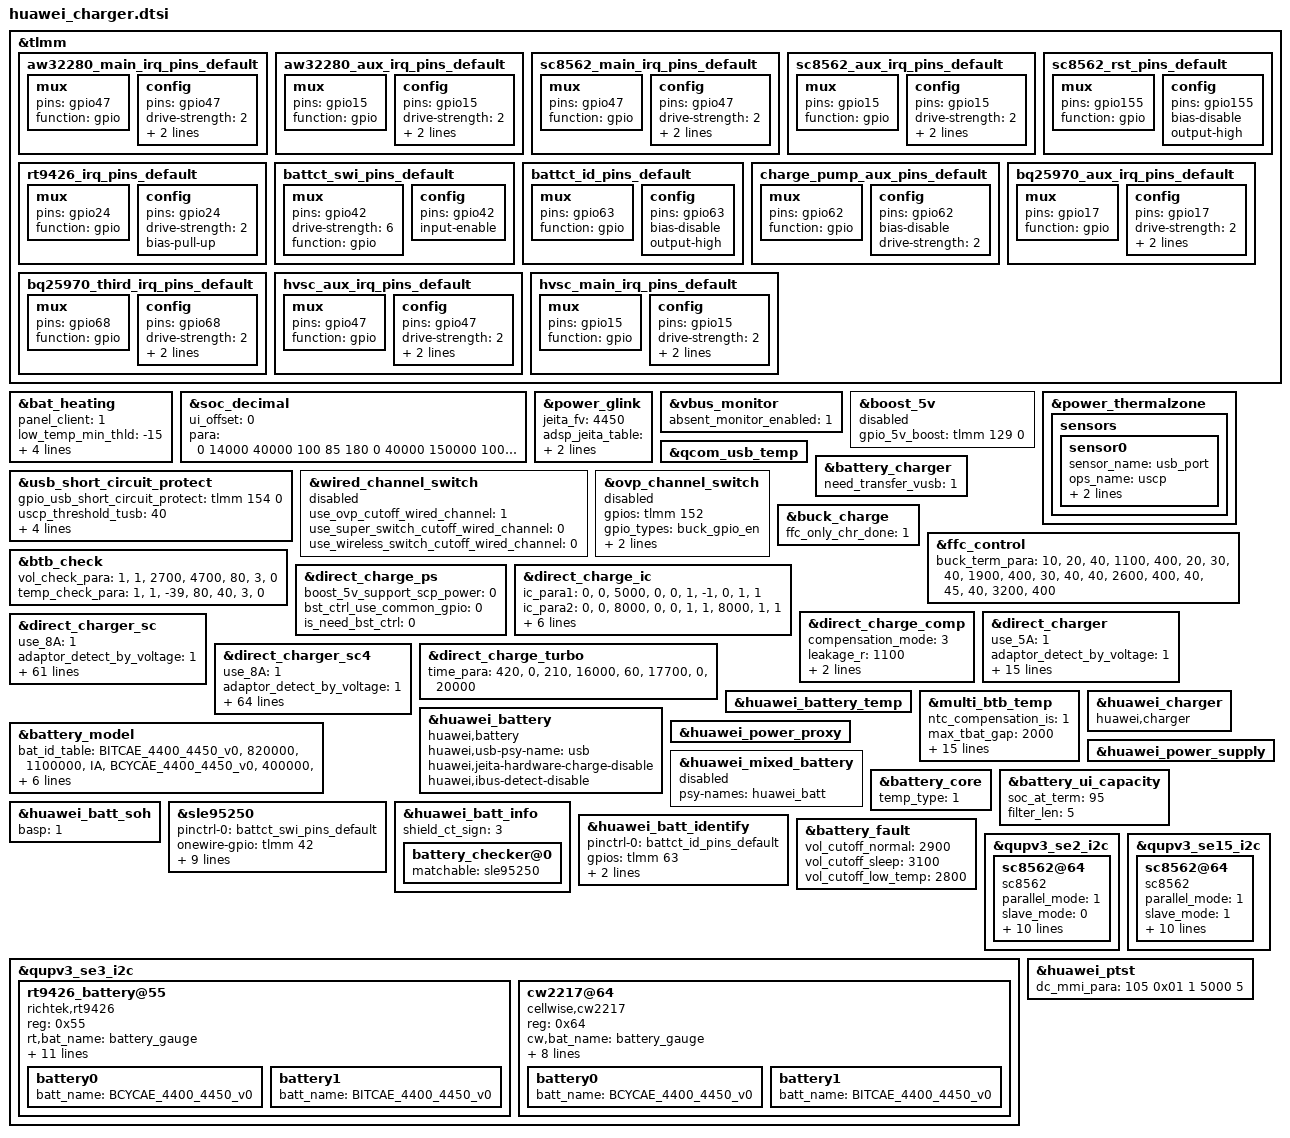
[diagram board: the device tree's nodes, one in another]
&tlmm {
	aw32280_main_irq_pins_default: aw32280_main_irq_pins_default {
		mux {
			pins = "gpio47";
			function = "gpio";
		};
		config {
			pins = "gpio47";
			drive-strength = <2>;
			bias-pull-up;
			input-enable;
		};
	};

	aw32280_aux_irq_pins_default: aw32280_aux_irq_pins_default {
		mux {
			pins = "gpio15";
			function = "gpio";
		};
		config {
			pins = "gpio15";
			drive-strength = <2>;
			bias-pull-up;
			input-enable;
		};
	};

	sc8562_main_irq_pins_default: sc8562_main_irq_pins_default {
		mux {
			pins = "gpio47";
			function = "gpio";
		};
		config {
			pins = "gpio47";
			drive-strength = <2>;
			bias-pull-up;
			input-enable;
		};
	};

	sc8562_aux_irq_pins_default: sc8562_aux_irq_pins_default {
		mux {
			pins = "gpio15";
			function = "gpio";
		};
		config {
			pins = "gpio15";
			drive-strength = <2>;
			bias-pull-up;
			input-enable;
		};
	};

	sc8562_rst_pins_default: sc8562_rst_pins_default {
		mux {
			pins = "gpio155";
			function = "gpio";
		};
		config {
			pins = "gpio155";
			bias-disable;
			output-high;
		};
	};

	rt9426_irq_pins_default: rt9426_irq_pins_default {
		mux {
			pins = "gpio24";
			function = "gpio";
		};
		config {
			pins = "gpio24";
			drive-strength = <2>;
			bias-pull-up;
		};
	};
	battct_swi_pins_default: battct_swi_pins_default {
		mux {
			pins = "gpio42";
			drive-strength = <6>;
			function = "gpio";
		};
		config {
			pins = "gpio42";
			input-enable;
		};
	};
	battct_id_pins_default: battct_id_pins_default {
		mux {
			pins = "gpio63";
			function = "gpio";
		};
		config {
			pins = "gpio63";
			bias-disable;
			output-high;
		};
	};
	charge_pump_aux_pins_default: charge_pump_aux_pins_default {
		/* MCLK4 */
		mux {
			pins = "gpio62";
			function = "gpio";
		};
		config {
			pins = "gpio62";
			bias-disable; /* No PULL */
			drive-strength = <2>; /* 2 MA */
		};
	};

	bq25970_aux_irq_pins_default: bq25970_aux_irq_pins_default {
		mux {
			pins = "gpio17";
			function = "gpio";
		};
		config {
			pins = "gpio17";
			drive-strength = <2>;
			bias-pull-up;
			input-enable;
		};
	};

	bq25970_third_irq_pins_default: bq25970_third_irq_pins_default {
		mux {
			pins = "gpio68";
			function = "gpio";
		};
		config {
			pins = "gpio68";
			drive-strength = <2>;
			bias-pull-up;
			input-enable;
		};
	};

	hvsc_aux_irq_pins_default: hvsc_aux_irq_pins_default {
		mux {
			pins = "gpio47";
			function = "gpio";
		};
		config {
			pins = "gpio47";
			drive-strength = <2>;
			bias-pull-up;
			input-enable;
		};
	};

	hvsc_main_irq_pins_default: hvsc_main_irq_pins_default {
		mux {
			pins = "gpio15";
			function = "gpio";
		};
		config {
			pins = "gpio15";
			drive-strength = <2>;
			bias-pull-up;
			input-enable;
		};
	};
};

&bat_heating {
	panel_client = "1";
	low_temp_min_thld = "-15";
	low_temp_min_ibat = "-550";
	buck_iin_limit = "750";
	temp_para =
		"-32767", "0", "0",
		"0", "5", "-1",
		"5", "10", "400",
		"10", "20", "2500",
		"20", "45", "4500",
		"45", "32767", "0";
	status = "ok";
};

&soc_decimal {
	ui_offset = <0>;
	para = <
		0 14000 40000  100 85  180
		0 40000 150000 100 120 100
		1 20000 27000  100 85  140
		1 27000 100000 100 85  140
	>;
	status = "ok";
};

&power_glink {
	jeita_fv = <4450>;
	adsp_jeita_table = <
		0 5 400 4450
		5 10 2000 4450
		10 45 3000 4450
		45 55 1400 4100
	>;
	battery_adc_channel = <1>;
};

&vbus_monitor {
	status = "ok";
	absent_monitor_enabled = <1>;
};

&boost_5v {
	gpio_5v_boost = <&tlmm 129 0>;    /* GPIO_07 */
	status = "disabled";
};

&power_thermalzone {
	status = "ok";
	sensors{
		sensor0 {
			sensor_name = "usb_port";
			ops_name = "uscp";
			adc_channel = <0>;
			ntc_index = <5>;
		};
	};
};

&qcom_usb_temp {
	status = "ok";
};

&battery_charger {
	need_transfer_vusb = <1>;
};

&usb_short_circuit_protect {
	gpio_usb_short_circuit_protect = <&tlmm 154 0>; /* GPIO_154 */
	uscp_threshold_tusb = <40>;
	open_mosfet_temp = <30>;
	close_mosfet_temp = <10>;
	open_hiz_temp = <30>;
	interval_switch_temp = <15>;
	status = "ok";
};

&wired_channel_switch {
	use_ovp_cutoff_wired_channel = <1>;
	use_super_switch_cutoff_wired_channel = <0>;
	use_wireless_switch_cutoff_wired_channel = <0>;
	status = "disabled";
};

&ovp_channel_switch {
	gpios = <&tlmm 152 0>;
	gpio_types = "buck_gpio_en";
	gpio_en_status = <0>;
	gpio_low_by_set_input = <0>;
	status = "disabled";
};
&buck_charge {
	ffc_only_chr_done = <1>;
	status = "ok";
};

&ffc_control {
	status = "ok";
	buck_term_para =
		"10", "20", "40", "1100", "400",
		"20", "30", "40", "1900", "400",
		"30", "40", "40", "2600", "400",
		"40", "45", "40", "3200", "400";
};

&btb_check {
	vol_check_para = "1", "1", "2700", "4700", "80", "3", "0";
	temp_check_para = "1", "1", "-39", "80", "40", "3", "0";
	status = "ok";
};

&direct_charge_ps {
	boost_5v_support_scp_power = <0>;
	bst_ctrl_use_common_gpio = <0>;
	is_need_bst_ctrl = <0>;
	status = "ok";
};

&direct_charge_ic {
	/* The IC_PARA table is used to find the relationship between chip and path */
	/* the chip's current passing capacity */
	/* and the sampling points of battery voltage and current */
	/* ic_index  path_index  max_ibat  ibat_sample_point  vbat_sample_point */
	ic_para1 =
		"0", "0", "5000", "0", "0",
		"1", "-1", "0", "1", "1";
	ic_para2 =
		"0", "0", "8000", "0", "0",
		"1", "1", "8000", "1", "1";
	ic_para3 =
		"0", "0", "12000", "0", "0",
		"1", "1", "12000", "1", "1";
	mode_para =
		"lvc_mode", "ic_para1",
		"sc_mode", "ic_para2",
		"sc4_mode", "ic_para3";
	use_two_stage = <0>;
	use_coul_ibat = <1>;
	use_coul_vbat = <0>;
	status = "ok";
};

&direct_charge_comp {
	compensation_mode = <3>;
	leakage_r = <1100>;
	compensate_r = <4>;
	/* The vbat_samp_point_para table is used to find the comp relationship between chips */
	/* Calculate all compensation values of the same index */
	/* as the final compensation of the chip */
	/* Separately calculate positive and negative poles */
	/* ic_index  p_index  n_index */
	vbat_samp_point_para =
		"0", "0", "0",
		"1", "1", "0";
	status = "ok";
};

&direct_charger {
	use_5A = <1>;
	adaptor_detect_by_voltage = <1>;
	need_wired_sw_off = <0>;
	volt_para =
		"4300", "5000", "4000",
		"4440", "4000", "1200";
	all_stage_compensate_r_en = <1>;
	cc_cable_detect_enable = <1>;
	vol_err_th = <250>;
	full_path_res_max = <300>;
	scp_work_on_charger = <1>;
	init_delt_vset = <300>;
	standard_cable_full_path_res_max = <300>;
	first_cc_stage_timer_in_min = <5>;
	stage_need_to_jump = "1";
	low_temp_hysteresis = <5>;
	temp_para =
		"-32767", "10", "0",
		"10", "45", "5000",
		"45", "32767", "0";
	rt_test_para =
		"1000", "105"; /* rt_curr_th rt_test_time */
	status = "ok";

};

&direct_charger_sc {
	use_8A = <1>;
	adaptor_detect_by_voltage = <1>;
	adaptor_antifake_check_enable = <1>;
	adaptor_antifake_key_index = <2>;
	dc_volt_ratio = <2>;
	cur_inversion = <3500>;
	max_adaptor_vset = <11000>;
	init_adapter_vset = <8800>;
	vol_err_th = <500>;
	adaptor_leakage_current_th = <600>;
	high_temp_hysteresis = <1>;
	init_delt_vset = <450>;
	vstep = <20>;
	min_dc_bat_vol = <3450>;
	max_dc_bat_vol = <4380>;
	delta_err = <200>;
	stop_charging_sleep_enable = <1>;
	support_multi_ic = <1>;
	multi_ic_ibat_th = <4000>;
	second_resist_check_en = <1>;
	ui_max_pwr = <40000>;
	product_max_pwr = <66000>;
	max_current_for_none_standard_cable = <6000>;
	volt_para =
		"4150", "13500", "8800",
		"4250", "8800", "6600",
		"4300", "6600", "4400",
		"4450", "4400", "3200",
		"4470", "3200", "1200";
	volt_para1 =
		"4100", "20000", "17600",
		"4250", "17600", "13200",
		"4300", "13200", "8800",
		"4400", "8800", "6600",
		"4450", "6600", "5300",
		"4470", "5300", "1900";
	volt_para2 =
		"4100", "20000", "17600",
		"4250", "17600", "13200",
		"4300", "13200", "8800",
		"4400", "8800", "6600",
		"4450", "6600", "5300",
		"4470", "5300", "2600";
	volt_para3 =
		"4100", "20000", "17600",
		"4250", "17600", "13200",
		"4300", "13200", "8800",
		"4400", "8800", "6600",
		"4450", "6600", "5300",
		"4470", "5300", "3200";
	time_para =
		"720", "8500",
		"540", "9000",
		"480", "11000",
		"0", "20000";
	bat_para =
		"CAE", "10", "20", "volt_para",
		"CAE", "20", "30", "volt_para1",
		"CAE", "30", "40", "volt_para2",
		"CAE", "40", "45", "volt_para3",
		"default", "10", "20", "volt_para",
		"default", "20", "30", "volt_para1",
		"default", "30", "40", "volt_para2",
		"default", "40", "45", "volt_para3";
	vstep_para =
			"2000", "80";
	cc_cable_detect_enable = <1>;
	full_path_res_max = <450>;
	scp_work_on_charger = <1>;
	standard_cable_full_path_res_max = <450>;
	first_cc_stage_timer_in_min = <14>;
	stage_need_to_jump = "-1";
	low_temp_hysteresis = <5>;
	rt_test_para =
		/* first:sc second:mainsc third:auxsc */
		"500", "105",
		"500", "105",
		"500", "105";
	current_ratio =
		"3", "7", "14", "2", "-1",
		"3", "8", "12", "1", "8000",
		"0", "8", "12", "0", "0";
	vbat_error =
		"3", "120", "2", "-1",
		"3", "80", "1", "0";
	temp_para =
		"-32767", "10", "0",
		"10", "45", "12500",
		"45", "32767", "0";
	resist_para =
		"0", "260", "6000",
		"260", "450", "4000";
	std_resist_para =
		"0", "300", "12000",
		"300", "450", "8000";
	second_resist_para =
		"0", "220", "12000",
		"220", "450", "8000";
	ctc_second_resist_para =
		"0", "250", "12000",
		"250", "450", "8000";
	status = "ok";
};

&direct_charger_sc4 {
	use_8A = <1>;
	adaptor_detect_by_voltage = <1>;
	adaptor_antifake_check_enable = <1>;
	adaptor_antifake_key_index = <2>;
	dc_volt_ratio = <4>;
	cur_inversion = <7500>;
	init_delt_vset = <900>;
	max_adaptor_vset = <20000>;
	init_adapter_vset = <15000>;
	vol_err_th = <500>;
	adaptor_leakage_current_th = <600>;
	high_temp_hysteresis = <1>;
	vstep = <40>;
	min_dc_bat_vol = <3450>;
	max_dc_bat_vol = <4380>;
	delta_err = <200>;
	multi_ic_ibat_th = <5000>;
	second_resist_check_en = <1>;
	ui_max_pwr = <40000>;
	product_max_pwr = <100000>;
	ctc_cable_full_path_res_max = <600>;
	max_current_for_none_standard_cable = <12000>;
	volt_para =
		"4150", "13500", "8800",
		"4250", "8800", "6600",
		"4300", "6600", "4600",
		"4450", "4600", "3400",
		"4470", "3400", "1100";
	volt_para1 =
		"4100", "20000", "17600",
		"4250", "17600", "13200",
		"4300", "13200", "9000",
		"4400", "9000", "6800",
		"4450", "6800", "5500",
		"4470", "5500", "1900";
	volt_para2 =
		"4100", "20000", "17600",
		"4250", "17600", "13200",
		"4300", "13200", "9000",
		"4400", "9000", "6800",
		"4450", "6800", "5500",
		"4470", "5500", "2600";
	volt_para3 =
		"4100", "20000", "17600",
		"4250", "17600", "13200",
		"4300", "13200", "9000",
		"4400", "9000", "6800",
		"4450", "6800", "5500",
		"4470", "5500", "3200";
	time_para =
		"300", "0",
		"180", "14000",
		"60", "16000",
		"0", "20000";
	bat_para =
		"CAE", "10", "20", "volt_para",
		"CAE", "20", "30", "volt_para1",
		"CAE", "30", "40", "volt_para2",
		"CAE", "40", "45", "volt_para3",
		"default", "10", "20", "volt_para",
		"default", "20", "30", "volt_para1",
		"default", "30", "40", "volt_para2",
		"default", "40", "45", "volt_para3";
	vstep_para =
			"2000", "80";
	all_stage_compensate_r_en = <1>;
	cc_cable_detect_enable = <1>;
	full_path_res_max = <450>;
	scp_work_on_charger = <1>;
	standard_cable_full_path_res_max = <450>;
	first_cc_stage_timer_in_min = <14>;
	stage_need_to_jump = "-1";
	low_temp_hysteresis = <5>;
	support_multi_ic = <1>;
	need_boost_5v = <0>;
	rt_test_para =
		/* first:sc second:mainsc third:auxsc */
		"500", "105",
		"500", "105",
		"500", "105";
	current_ratio =
		"3", "8", "14", "2", "-1",
		"3", "7", "12", "1", "8000",
		"0", "7", "12", "0", "0";
	vbat_error =
		"3", "120", "2", "-1",
		"3", "80", "1", "0";
	temp_para =
		"-32767", "10", "0",
		"10", "45", "20000",
		"45", "32767", "0";
	resist_para =
		"0", "260", "12000",
		"260", "450", "8000";
	std_resist_para =
		"0", "300", "20000",
		"300", "450", "16000";
	second_resist_para =
		"0", "260", "20000",
		"260", "450", "16000";
	ctc_second_resist_para =
		"0", "250", "20000",
		"250", "450", "16000";
	status = "ok";
};

&direct_charge_turbo {
	status = "ok";
        time_para =
                "420", "0",
                "210", "16000",
                "60", "17700",
                "0", "20000";
};

&huawei_battery_temp {
	status = "ok";
};

&multi_btb_temp {
	status = "ok";
	ntc_compensation_is = <1>;
	max_tbat_gap = <2000>;
	comp_para =
		"17000", "28000",
		"15000", "25000",
		"14000", "23000",
		"13000", "20000",
		"11000", "16000",
		"10000", "13000",
		"9000", "12000",
		"7000", "10000",
		"6000", "8000",
		"5000", "6000",
		"4000", "4000",
		"3000", "3000",
		"2000", "2000";
	comp_para1 =
		"0", "0";
	comp_para_fix =
		"17000", "19000",
		"15000", "17000",
		"14000", "15000",
		"13000", "14000",
		"11000", "12000",
		"10000", "11000",
		"9000", "9000",
		"8000", "8000",
		"6000", "7000",
		"5000", "5000",
		"4000", "4000",
		"3000", "3000",
		"2000", "2000";
	need_different_comp = <1>; /* config "1" if different battery type use different comp para */
	/* By default, only 2 columns of sensor-names need to be configured */
	/* just if need_different_comp is "1", 3 columns of sensor-names need to be configured */
	/* sensor name, default compensation para, compensation para for another battery type */
	sensor-names =
		"battery_gauge", "comp_para", "comp_para_fix",
		"bk_battery", "comp_para1", "comp_para1";
};

&huawei_battery {
	compatible = "huawei,battery";
	status = "ok";
	huawei,usb-psy-name = "usb";
	huawei,jeita-hardware-charge-disable;
	huawei,ibus-detect-disable;
};

&huawei_charger {
	compatible = "huawei,charger";
	status = "ok";
};


&battery_model {
	bat_id_table =
		"BITCAE_4400_4450_v0", "820000", "1100000", "IA",
		"BCYCAE_4400_4450_v0", "400000", "630000", "CA";
	design_fcc = <4400>;
	id_adc_channel = <0>; /* useless but necessary for Qcom, set 0 as default */
	bat_identifier_index = <10>; /* the 11th digit of sn is used as identifier */
	bat_identifier_len = <1>; /* the length of identifier */
	bat_types_pattern =
		"cob", "[B]";
	status = "ok";
};

&huawei_power_proxy {
	status = "ok";
};

&huawei_power_supply {
	 status = "ok";
};

&huawei_mixed_battery {
	psy-names = "huawei_batt";
	status = "disabled";
};

&battery_core {
	temp_type = <1>;
	status = "ok";
};

&battery_ui_capacity {
	soc_at_term = <95>;
	filter_len = <5>;
	status = "ok";
};

&huawei_batt_soh {
	basp = <1>;
	status = "ok";
};

&sle95250 {
        pinctrl-names = "default";
        pinctrl-0 = <&battct_swi_pins_default>;
        onewire-gpio = <&tlmm 42 0>;
        product_id0 = <1>;
        product_id2 = <3>;
        gpio_sn_mode_val = <0>;
        dip_check = <0>;
        gpio_swi = <42>;
        gpio_id_mode = <63>;
        gpio_swi_drv = <2>;
        tau = /bits/ 8 <0xa>;
        tau_fastboot = <7>;
        status = "ok";
};

&huawei_batt_info {
        status = "ok";
        shield_ct_sign = <3>;
        battery_checker@0 {
                matchable = <&sle95250>;
                status = "ok";
        };
};

&huawei_batt_identify {
	pinctrl-names = "default";
	pinctrl-0 = <&battct_id_pins_default>;
	gpios = <&tlmm 63 0>;
	id_voltage_gpiov = <0 1>;
	id_sn_gpiov = <0 0>;
	status = "ok";
};

&battery_fault {
	vol_cutoff_normal = <2900>;
	vol_cutoff_sleep = <3100>;
	vol_cutoff_low_temp = <2800>;
	status = "ok";
};

&qupv3_se2_i2c {
	#address-cells = <1>;
	#size-cells = <0>;
	status = "ok";
	sc8562@64{
		compatible = "sc8562";
		parallel_mode = <1>;
		slave_mode = <0>;
		ic_role = <0>;
		reg = <0x64>;
		gpio_reset = <&tlmm 155 0>;
		fcp_support = <1>;
		scp_support = <1>;
		pinctrl-names = "default";
		pinctrl-0 = <&sc8562_main_irq_pins_default>;
		gpio_int = <&tlmm 47 0>;
		gpio_enable = <&tlmm 62 0>;
		sense_r_config = <10>;
		sense_r_actual = <10>;
		status = "ok";
	};
};

&qupv3_se3_i2c {
	#address-cells = <1>;
	#size-cells = <0>;
	status = "ok";
	rt9426_battery@55{
		reg = <0x55>;
		compatible = "richtek,rt9426";
		rt,bat_name = "battery_gauge";
		pinctrl-names = "default";
		pinctrl-0 = <&rt9426_irq_pins_default>;
		rt9426,gpio-intb = <&tlmm 24 0x0>;
		need_reset_version = <9>;
		rt_config_ver = <17>;
		lowtemp_en = <1>;
		ntc_compensation_is = <1>;
		ground_loop_comp_en = <1>;
		ground_loop_comp_rcomp = <20>;
		ntc_temp_compensation_para =
			"17000", "170",
			"15000", "150",
			"13000", "130",
			"11000", "110",
			"9000", "80",
			"7000", "50",
			"6000", "40",
			"5000", "30",
			"3000", "20",
			"2000", "10";
		status = "ok";
		battery0{
			batt_name = "BCYCAE_4400_4450_v0";
			#include "../../../huawei_charger/rt9426_0P5mohm_BCYCAE_4400mAh_4V45_GLA_BT249.dtsi"
		};
		battery1{
			batt_name = "BITCAE_4400_4450_v0";
			#include "../../../huawei_charger/rt9426_0P5mohm_BITCAE_4400mAh_4V45_GLA_BT249.dtsi"
		};
	};

	cw2217@64 {
		compatible = "cellwise,cw2217";
		reg = <0x64>;
		cw,bat_name = "battery_gauge";
		status = "ok";
		ground_loop_comp_en = <1>;
		ground_loop_comp_rcomp = <20>;
		en_soft_reset = <1>;
		vbat_soc_table =
			"3799", "3823", "33",
			"3823", "3850", "39",
			"3850", "3882", "46",
			"3882", "3928", "52",
			"3928", "3998", "59",
			"3998", "4057", "65",
			"4057", "4121", "71",
			"4121", "4191", "78",
			"4191", "4262", "84",
			"4262", "4330", "90",
			"4330", "4390", "97";
		battery0{
			batt_name = "BCYCAE_4400_4450_v0";
			#include "../../../huawei_charger/cw2217_0P5mohm_BCYCAE_4400mAh_4V45_GLA_BT249.dtsi"
		};
		battery1{
			batt_name = "BITCAE_4400_4450_v0";
			#include "../../../huawei_charger/cw2217_0P5mohm_BITCAE_4400mAh_4V45_GLA_BT249.dtsi"
		};
	};

};

&qupv3_se15_i2c {
	#address-cells = <1>;
	#size-cells = <0>;
	status = "ok";
	sc8562@64{
		compatible = "sc8562";
		parallel_mode = <1>;
		slave_mode = <1>;
		ic_role = <1>;
		reg = <0x64>;
		gpio_reset = <&tlmm 17 0>;
		fcp_support = <0>;
		scp_support = <0>;
		pinctrl-names = "default";
		pinctrl-0 = <&sc8562_aux_irq_pins_default>;
		gpio_int = <&tlmm 15 0>;
		gpio_enable = <&tlmm 46 0>;
		sense_r_config = <10>;
		sense_r_actual = <10>;
		status = "ok";
	};
};

&huawei_ptst {
	dc_mmi_para = <105 0x01 1 5000 5>;
	status = "ok";
};
